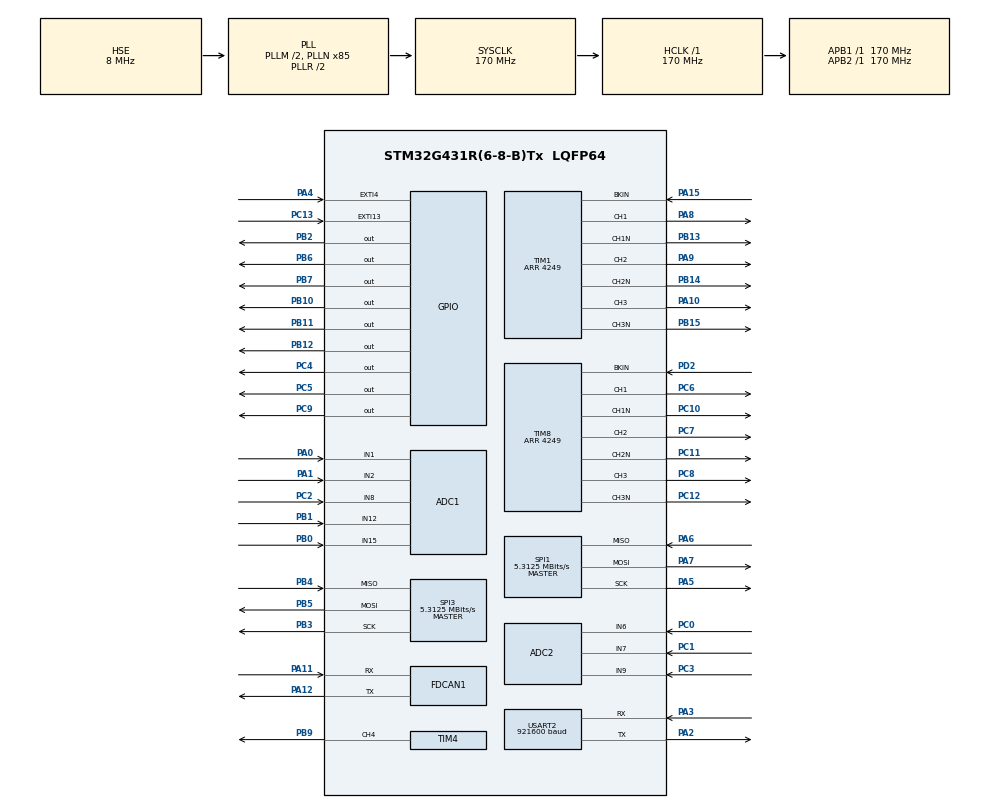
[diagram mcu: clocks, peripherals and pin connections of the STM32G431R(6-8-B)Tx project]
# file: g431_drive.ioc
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ADC1.Channel-0\#ChannelRegularConversion=ADC_CHANNEL_8
ADC1.Channel-4\#ChannelRegularConversion=ADC_CHANNEL_15
ADC1.Channel-5\#ChannelRegularConversion=ADC_CHANNEL_12
ADC1.Channel-6\#ChannelRegularConversion=ADC_CHANNEL_VREFINT
ADC1.EnableAnalogWatchDog3=false
ADC1.EnableInjectedConversion=ENABLE
ADC1.ExternalTrigConv=ADC_SOFTWARE_START
ADC1.ExternalTrigInjecConv=ADC_EXTERNALTRIGINJEC_T8_TRGO2
ADC1.InjNumberOfConversion=2
ADC1.InjectedChannel-2\#ChannelInjectedConversion=ADC_CHANNEL_1
ADC1.InjectedChannel-3\#ChannelInjectedConversion=ADC_CHANNEL_2
ADC1.InjectedOffsetNumber-2\#ChannelInjectedConversion=ADC_OFFSET_NONE
ADC1.InjectedOffsetNumber-3\#ChannelInjectedConversion=ADC_OFFSET_NONE
ADC1.InjectedRank-2\#ChannelInjectedConversion=1
ADC1.InjectedRank-3\#ChannelInjectedConversion=2
ADC1.InjectedSamplingTime-2\#ChannelInjectedConversion=ADC_SAMPLETIME_6CYCLES_5
ADC1.InjectedSamplingTime-3\#ChannelInjectedConversion=ADC_SAMPLETIME_6CYCLES_5
ADC1.NbrOfConversion=4
ADC1.NbrOfConversionFlag=1
ADC1.OffsetNumber-0\#ChannelRegularConversion=ADC_OFFSET_NONE
ADC1.OffsetNumber-4\#ChannelRegularConversion=ADC_OFFSET_NONE
ADC1.OffsetNumber-5\#ChannelRegularConversion=ADC_OFFSET_NONE
ADC1.OffsetNumber-6\#ChannelRegularConversion=ADC_OFFSET_NONE
ADC1.OversamplingMode=DISABLE
ADC1.Rank-0\#ChannelRegularConversion=1
ADC1.Rank-4\#ChannelRegularConversion=2
ADC1.Rank-5\#ChannelRegularConversion=3
ADC1.Rank-6\#ChannelRegularConversion=4
ADC1.SamplingTime-0\#ChannelRegularConversion=ADC_SAMPLETIME_92CYCLES_5
ADC1.SamplingTime-4\#ChannelRegularConversion=ADC_SAMPLETIME_92CYCLES_5
ADC1.SamplingTime-5\#ChannelRegularConversion=ADC_SAMPLETIME_92CYCLES_5
ADC1.SamplingTime-6\#ChannelRegularConversion=ADC_SAMPLETIME_247CYCLES_5
ADC1.master=1
ADC2.Channel-0\#ChannelRegularConversion=ADC_CHANNEL_9
ADC2.EnableInjectedConversion=ENABLE
ADC2.ExternalTrigConv=ADC_SOFTWARE_START
ADC2.ExternalTrigInjecConv=ADC_EXTERNALTRIGINJEC_T1_TRGO2
ADC2.InjNumberOfConversion=2
ADC2.InjectedChannel-1\#ChannelInjectedConversion=ADC_CHANNEL_6
ADC2.InjectedChannel-6\#ChannelInjectedConversion=ADC_CHANNEL_7
ADC2.InjectedOffsetNumber-1\#ChannelInjectedConversion=ADC_OFFSET_NONE
ADC2.InjectedOffsetNumber-6\#ChannelInjectedConversion=ADC_OFFSET_NONE
ADC2.InjectedRank-1\#ChannelInjectedConversion=1
ADC2.InjectedRank-6\#ChannelInjectedConversion=2
ADC2.InjectedSamplingTime-1\#ChannelInjectedConversion=ADC_SAMPLETIME_6CYCLES_5
ADC2.InjectedSamplingTime-6\#ChannelInjectedConversion=ADC_SAMPLETIME_6CYCLES_5
ADC2.NbrOfConversionFlag=1
ADC2.OffsetNumber-0\#ChannelRegularConversion=ADC_OFFSET_NONE
ADC2.Rank-0\#ChannelRegularConversion=1
ADC2.Rank1_Channel=ADC_CHANNEL_6
ADC2.Rank2_Channel=ADC_CHANNEL_7
ADC2.SamplingTime-0\#ChannelRegularConversion=ADC_SAMPLETIME_6CYCLES_5
Dma.Request0=USART2_TX
Dma.Request1=USART2_RX
Dma.USART2_RX.1.Direction=DMA_PERIPH_TO_MEMORY
Dma.USART2_RX.1.EventEnable=DISABLE
Dma.USART2_RX.1.Instance=DMA1_Channel2
Dma.USART2_RX.1.MemDataAlignment=DMA_MDATAALIGN_BYTE
Dma.USART2_RX.1.MemInc=DMA_MINC_ENABLE
Dma.USART2_RX.1.Mode=DMA_CIRCULAR
Dma.USART2_RX.1.PeriphDataAlignment=DMA_PDATAALIGN_BYTE
Dma.USART2_RX.1.PeriphInc=DMA_PINC_DISABLE
Dma.USART2_RX.1.Polarity=HAL_DMAMUX_REQ_GEN_RISING
Dma.USART2_RX.1.Priority=DMA_PRIORITY_LOW
Dma.USART2_RX.1.RequestNumber=1
Dma.USART2_RX.1.SignalID=NONE
Dma.USART2_RX.1.SyncEnable=DISABLE
Dma.USART2_RX.1.SyncPolarity=HAL_DMAMUX_SYNC_NO_EVENT
Dma.USART2_RX.1.SyncRequestNumber=1
Dma.USART2_RX.1.SyncSignalID=NONE
Dma.USART2_TX.0.Direction=DMA_MEMORY_TO_PERIPH
Dma.USART2_TX.0.EventEnable=DISABLE
Dma.USART2_TX.0.Instance=DMA1_Channel1
Dma.USART2_TX.0.MemDataAlignment=DMA_MDATAALIGN_BYTE
Dma.USART2_TX.0.MemInc=DMA_MINC_ENABLE
Dma.USART2_TX.0.Mode=DMA_NORMAL
Dma.USART2_TX.0.PeriphDataAlignment=DMA_PDATAALIGN_BYTE
Dma.USART2_TX.0.PeriphInc=DMA_PINC_DISABLE
Dma.USART2_TX.0.Polarity=HAL_DMAMUX_REQ_GEN_RISING
Dma.USART2_TX.0.Priority=DMA_PRIORITY_LOW
Dma.USART2_TX.0.RequestNumber=1
Dma.USART2_TX.0.SignalID=NONE
Dma.USART2_TX.0.SyncEnable=DISABLE
Dma.USART2_TX.0.SyncPolarity=HAL_DMAMUX_SYNC_NO_EVENT
Dma.USART2_TX.0.SyncRequestNumber=1
Dma.USART2_TX.0.SyncSignalID=NONE
FDCAN1.AutoRetransmission=ENABLE
FDCAN1.CalculateBaudRateNominal=500000
FDCAN1.CalculateTimeBitNominal=2000
FDCAN1.CalculateTimeQuantumNominal=125.0
FDCAN1.DataTimeSeg1=12
FDCAN1.DataTimeSeg2=3
FDCAN1.NominalPrescaler=1
FDCAN1.NominalTimeSeg1=12
FDCAN1.NominalTimeSeg2=3
FDCAN1.ProtocolException=DISABLE
FDCAN1.TransmitPause=DISABLE
IWDG.Prescaler=IWDG_PRESCALER_32
IWDG.Reload=40
IWDG.Window=20
Mcu.Family=STM32G4
Mcu.Name=STM32G431R(6-8-B)Tx
Mcu.Package=LQFP64
NVIC.ADC1_2_IRQn=true\:1\:0\:true\:false\:true\:true\:true\:true
NVIC.DMA1_Channel1_IRQn=true\:4\:0\:true\:false\:true\:false\:true\:true
NVIC.DMA1_Channel2_IRQn=true\:4\:0\:true\:false\:true\:false\:true\:true
NVIC.EXTI15_10_IRQn=true\:2\:0\:true\:false\:true\:true\:true\:true
NVIC.EXTI4_IRQn=true\:2\:0\:true\:false\:true\:true\:true\:true
NVIC.FDCAN1_IT0_IRQn=true\:3\:0\:true\:false\:true\:true\:true\:true
NVIC.PriorityGroup=NVIC_PRIORITYGROUP_4
NVIC.RCC_IRQn=true\:0\:0\:false\:false\:true\:true\:false\:true
NVIC.TIM1_BRK_TIM15_IRQn=true\:0\:0\:false\:false\:true\:true\:true\:true
NVIC.TIM8_BRK_IRQn=true\:0\:0\:false\:false\:true\:true\:true\:true
NVIC.USART2_IRQn=true\:4\:0\:true\:false\:true\:true\:true\:true
PA0.Mode=IN1-Single-Ended
PA0.Signal=ADC1_IN1
PA1.Mode=IN2-Single-Ended
PA1.Signal=ADC1_IN2
PA10.Signal=S_TIM1_CH3
PA11.Mode=FDCAN_Activate
PA11.Signal=FDCAN1_RX
PA12.Mode=FDCAN_Activate
PA12.Signal=FDCAN1_TX
PA13.Mode=Serial_Wire
PA13.Signal=SYS_JTMS-SWDIO
PA14.Mode=Serial_Wire
PA14.Signal=SYS_JTCK-SWCLK
PA15.Mode=Activate-Break-Input
PA15.Signal=TIM1_BKIN
PA2.Mode=Asynchronous
PA2.Signal=USART2_TX
PA3.Mode=Asynchronous
PA3.Signal=USART2_RX
PA4.GPIO_ModeDefaultEXTI=GPIO_MODE_IT_FALLING
PA4.GPIO_PuPd=GPIO_NOPULL
PA4.Signal=GPXTI4
PA5.GPIO_Speed=GPIO_SPEED_FREQ_MEDIUM
PA5.Mode=Full_Duplex_Master
PA5.Signal=SPI1_SCK
PA6.GPIO_Speed=GPIO_SPEED_FREQ_MEDIUM
PA6.Mode=Full_Duplex_Master
PA6.Signal=SPI1_MISO
PA7.GPIO_Speed=GPIO_SPEED_FREQ_MEDIUM
PA7.Mode=Full_Duplex_Master
PA7.Signal=SPI1_MOSI
PA8.Signal=S_TIM1_CH1
PA9.Signal=S_TIM1_CH2
PB0.Mode=IN15-Single-Ended
PB0.Signal=ADC1_IN15
PB1.Mode=IN12-Single-Ended
PB1.Signal=ADC1_IN12
PB10.GPIO_ModeDefaultOutputPP=GPIO_MODE_OUTPUT_PP
PB10.GPIO_Speed=GPIO_SPEED_FREQ_LOW
PB10.PinState=GPIO_PIN_RESET
PB10.Signal=GPIO_Output
PB11.GPIO_ModeDefaultOutputPP=GPIO_MODE_OUTPUT_PP
PB11.GPIO_Speed=GPIO_SPEED_FREQ_LOW
PB11.PinState=GPIO_PIN_SET
PB11.Signal=GPIO_Output
PB12.GPIO_ModeDefaultOutputPP=GPIO_MODE_OUTPUT_PP
PB12.GPIO_Speed=GPIO_SPEED_FREQ_LOW
PB12.PinState=GPIO_PIN_SET
PB12.Signal=GPIO_Output
PB13.Mode=PWM Generation1 CH1 CH1N
PB13.Signal=TIM1_CH1N
PB14.Mode=PWM Generation2 CH2 CH2N
PB14.Signal=TIM1_CH2N
PB15.Mode=PWM Generation3 CH3 CH3N
PB15.Signal=TIM1_CH3N
PB2.GPIO_ModeDefaultOutputPP=GPIO_MODE_OUTPUT_PP
PB2.GPIO_Speed=GPIO_SPEED_FREQ_LOW
PB2.PinState=GPIO_PIN_RESET
PB2.Signal=GPIO_Output
PB3.GPIO_Speed=GPIO_SPEED_FREQ_MEDIUM
PB3.Mode=Full_Duplex_Master
PB3.Signal=SPI3_SCK
PB4.GPIO_Speed=GPIO_SPEED_FREQ_MEDIUM
PB4.Mode=Full_Duplex_Master
PB4.Signal=SPI3_MISO
PB5.GPIO_Speed=GPIO_SPEED_FREQ_MEDIUM
PB5.Mode=Full_Duplex_Master
PB5.Signal=SPI3_MOSI
PB6.GPIO_ModeDefaultOutputPP=GPIO_MODE_OUTPUT_PP
PB6.GPIO_Speed=GPIO_SPEED_FREQ_LOW
PB6.PinState=GPIO_PIN_SET
PB6.Signal=GPIO_Output
PB7.GPIO_ModeDefaultOutputPP=GPIO_MODE_OUTPUT_PP
PB7.GPIO_Speed=GPIO_SPEED_FREQ_LOW
PB7.PinState=GPIO_PIN_SET
PB7.Signal=GPIO_Output
PB9.Signal=S_TIM4_CH4
PC0.Mode=IN6-Single-Ended
PC0.Signal=ADC2_IN6
PC1.Mode=IN7-Single-Ended
PC1.Signal=ADC2_IN7
PC10.Mode=PWM Generation1 CH1 CH1N
PC10.Signal=TIM8_CH1N
PC11.Mode=PWM Generation2 CH2 CH2N
PC11.Signal=TIM8_CH2N
PC12.Mode=PWM Generation3 CH3 CH3N
PC12.Signal=TIM8_CH3N
PC13.GPIO_ModeDefaultEXTI=GPIO_MODE_IT_FALLING
PC13.Signal=GPXTI13
PC2.Mode=IN8-Single-Ended
PC2.Signal=ADC1_IN8
PC3.Mode=IN9-Single-Ended
PC3.Signal=ADC2_IN9
PC4.GPIO_ModeDefaultOutputPP=GPIO_MODE_OUTPUT_PP
PC4.GPIO_Speed=GPIO_SPEED_FREQ_LOW
PC4.PinState=GPIO_PIN_SET
PC4.Signal=GPIO_Output
PC5.GPIO_ModeDefaultOutputPP=GPIO_MODE_OUTPUT_PP
PC5.GPIO_Speed=GPIO_SPEED_FREQ_LOW
PC5.PinState=GPIO_PIN_SET
PC5.Signal=GPIO_Output
PC6.Signal=S_TIM8_CH1
PC7.Signal=S_TIM8_CH2
PC8.Signal=S_TIM8_CH3
PC9.GPIO_ModeDefaultOutputPP=GPIO_MODE_OUTPUT_PP
PC9.GPIO_Speed=GPIO_SPEED_FREQ_LOW
PC9.PinState=GPIO_PIN_SET
PC9.Signal=GPIO_Output
PD2.Mode=Activate-Break-Input
PD2.Signal=TIM8_BKIN
PF0-OSC_IN.Mode=HSE-External-Oscillator
PF0-OSC_IN.Signal=RCC_OSC_IN
PF1-OSC_OUT.Mode=HSE-External-Oscillator
PF1-OSC_OUT.Signal=RCC_OSC_OUT
ProjectManager.HeapSize=0x200
ProjectManager.StackSize=0x400
ProjectManager.TargetToolchain=MDK-ARM V5.32
RCC.ADC12Freq_Value=170000000
RCC.AHBFreq_Value=170000000
RCC.APB1Freq_Value=170000000
RCC.APB1TimFreq_Value=170000000
RCC.APB2Freq_Value=170000000
RCC.APB2TimFreq_Value=170000000
RCC.CortexFreq_Value=170000000
RCC.EXTERNAL_CLOCK_VALUE=12288000
RCC.EnbaleCSS=true
RCC.FDCANCLockSelection=RCC_FDCANCLKSOURCE_HSE
RCC.HCLKFreq_Value=170000000
RCC.HSE_VALUE=8000000
RCC.HSI48_VALUE=48000000
RCC.HSI_VALUE=16000000
RCC.LSE_VALUE=32768
RCC.PLLM=RCC_PLLM_DIV2
RCC.PLLN=85
RCC.PLLSourceVirtual=RCC_PLLSOURCE_HSE
RCC.SYSCLKFreq_VALUE=170000000
RCC.SYSCLKSource=RCC_SYSCLKSOURCE_PLLCLK
RCC.USBFreq_Value=170000000
RCC.VCOOutputFreq_Value=340000000
SH.S_TIM1_CH1.0=TIM1_CH1,PWM Generation1 CH1 CH1N
SH.S_TIM1_CH2.0=TIM1_CH2,PWM Generation2 CH2 CH2N
SH.S_TIM1_CH3.0=TIM1_CH3,PWM Generation3 CH3 CH3N
SH.S_TIM4_CH4.0=TIM4_CH4,PWM Generation4 CH4
SH.S_TIM8_CH1.0=TIM8_CH1,PWM Generation1 CH1 CH1N
SH.S_TIM8_CH2.0=TIM8_CH2,PWM Generation2 CH2 CH2N
SH.S_TIM8_CH3.0=TIM8_CH3,PWM Generation3 CH3 CH3N
SPI1.BaudRatePrescaler=SPI_BAUDRATEPRESCALER_32
SPI1.CLKPhase=SPI_PHASE_2EDGE
SPI1.CLKPolarity=SPI_POLARITY_HIGH
SPI1.CalculateBaudRate=5.3125 MBits/s
SPI1.DataSize=SPI_DATASIZE_8BIT
SPI1.Direction=SPI_DIRECTION_2LINES
SPI1.Mode=SPI_MODE_MASTER
SPI1.VirtualType=VM_MASTER
SPI3.BaudRatePrescaler=SPI_BAUDRATEPRESCALER_32
SPI3.CLKPhase=SPI_PHASE_2EDGE
SPI3.CLKPolarity=SPI_POLARITY_HIGH
SPI3.CalculateBaudRate=5.3125 MBits/s
SPI3.DataSize=SPI_DATASIZE_8BIT
SPI3.Direction=SPI_DIRECTION_2LINES
SPI3.Mode=SPI_MODE_MASTER
SPI3.VirtualType=VM_MASTER
TIM1.Break2Polarity=TIM_BREAK2POLARITY_LOW
TIM1.BreakFilter=3
TIM1.BreakPolarity=TIM_BREAKPOLARITY_LOW
TIM1.Channel-PWM\ Generation1\ CH1\ CH1N=TIM_CHANNEL_1
TIM1.Channel-PWM\ Generation2\ CH2\ CH2N=TIM_CHANNEL_2
TIM1.Channel-PWM\ Generation3\ CH3\ CH3N=TIM_CHANNEL_3
TIM1.Channel-PWM\ Generation5\ No\ Output=TIM_CHANNEL_5
TIM1.CounterMode=TIM_COUNTERMODE_CENTERALIGNED1
TIM1.LockLevel=TIM_LOCKLEVEL_3
TIM1.PeriodNoDither=4249
TIM1.PulseNoDither_5=4200
TIM1.TIM_MasterOutputTrigger2=TIM_TRGO2_OC5REF
TIM4.Channel-PWM\ Generation4\ CH4=TIM_CHANNEL_4
TIM4.PeriodNoDither=99
TIM4.Prescaler=169
TIM8.Break2Polarity=TIM_BREAK2POLARITY_LOW
TIM8.BreakFilter=3
TIM8.BreakPolarity=TIM_BREAKPOLARITY_LOW
TIM8.Channel-PWM\ Generation1\ CH1\ CH1N=TIM_CHANNEL_1
TIM8.Channel-PWM\ Generation2\ CH2\ CH2N=TIM_CHANNEL_2
TIM8.Channel-PWM\ Generation3\ CH3\ CH3N=TIM_CHANNEL_3
TIM8.Channel-PWM\ Generation5\ No\ Output=TIM_CHANNEL_5
TIM8.CounterMode=TIM_COUNTERMODE_CENTERALIGNED1
TIM8.LockLevel=TIM_LOCKLEVEL_3
TIM8.PeriodNoDither=4249
TIM8.PulseNoDither_5=4200
TIM8.TIM_MasterOutputTrigger2=TIM_TRGO2_OC5REF
USART2.BaudRate=921600
USART2.VirtualMode-Asynchronous=VM_ASYNC
VP_ADC1_Vref_Input.Mode=IN-Vrefint
VP_IWDG_VS_IWDG.Mode=IWDG_Activate
VP_SYS_VS_DBSignals.Mode=DisableDeadBatterySignals
VP_TIM1_VS_ClockSourceINT.Mode=Internal
VP_TIM1_VS_no_output5.Mode=PWM Generation5 No Output
VP_TIM4_VS_ClockSourceINT.Mode=Internal
VP_TIM8_VS_ClockSourceINT.Mode=Internal
VP_TIM8_VS_no_output5.Mode=PWM Generation5 No Output
board=custom

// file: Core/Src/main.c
/* USER CODE BEGIN Header */
/**
  ******************************************************************************
  * @file           : main.c
  * @brief          : Main program body
  ******************************************************************************
  * @attention
  *
  * Copyright (c) 2026 STMicroelectronics.
  * All rights reserved.
  *
  * This software is licensed under terms that can be found in the LICENSE file
  * in the root directory of this software component.
  * If no LICENSE file comes with this software, it is provided AS-IS.
  *
  ******************************************************************************
  */
/* USER CODE END Header */
#include "main.h"
#include "adc.h"
#include "dma.h"
#include "fdcan.h"
#include "spi.h"
#include "tim.h"
#include "usart.h"
#include "gpio.h"

/* USER CODE BEGIN Includes */

#include "headline.h" /* 统一 include 入口：HAL、标准库与全部模块头在此聚合，各 .c 只 include 本头文件（约定见端级 CLAUDE.md） */

/* USER CODE END Includes */

void SystemClock_Config(void);

int main(void)
{

  /* MCU Configuration--------------------------------------------------------*/

  /* Reset of all peripherals, Initializes the Flash interface and the Systick. */
  HAL_Init();

  /* Configure the system clock */
  SystemClock_Config();

  /* Initialize all configured peripherals */
  MX_GPIO_Init();
  MX_DMA_Init();
  MX_TIM1_Init();
  MX_ADC1_Init();
  MX_ADC2_Init();
  MX_TIM4_Init();
  MX_TIM8_Init();
  MX_USART2_UART_Init();
  MX_FDCAN1_Init();
  MX_SPI1_Init();
  MX_SPI3_Init();
  /* USER CODE BEGIN 2 */

  app_init(); /* 统一初始化入口：各模块初始化在此聚合，各 .c 只调用本函数（约定见端级 CLAUDE.md） */

  /* USER CODE END 2 */

  /* Infinite loop */
  /* USER CODE BEGIN WHILE */
  while (1)
  {

    app_main(); /* 统一主循环入口：各模块主循环在此聚合，各 .c 只调用本函数（约定见端级 CLAUDE.md） */

    /* USER CODE END WHILE */

  }
}

void SystemClock_Config(void)
{
  RCC_OscInitTypeDef RCC_OscInitStruct = {0};
  RCC_ClkInitTypeDef RCC_ClkInitStruct = {0};

  /** Configure the main internal regulator output voltage
  */
  HAL_PWREx_ControlVoltageScaling(PWR_REGULATOR_VOLTAGE_SCALE1_BOOST);

  /** Initializes the RCC Oscillators according to the specified parameters
  * in the RCC_OscInitTypeDef structure.
  */
  RCC_OscInitStruct.OscillatorType = RCC_OSCILLATORTYPE_LSI|RCC_OSCILLATORTYPE_HSE;
  RCC_OscInitStruct.HSEState = RCC_HSE_ON;
  RCC_OscInitStruct.LSIState = RCC_LSI_ON;
  RCC_OscInitStruct.PLL.PLLState = RCC_PLL_ON;
  RCC_OscInitStruct.PLL.PLLSource = RCC_PLLSOURCE_HSE;
  RCC_OscInitStruct.PLL.PLLM = RCC_PLLM_DIV2;
  RCC_OscInitStruct.PLL.PLLN = 85;
  RCC_OscInitStruct.PLL.PLLP = RCC_PLLP_DIV2;
  RCC_OscInitStruct.PLL.PLLQ = RCC_PLLQ_DIV2;
  RCC_OscInitStruct.PLL.PLLR = RCC_PLLR_DIV2;
  if (HAL_RCC_OscConfig(&RCC_OscInitStruct) != HAL_OK)
  {
    Error_Handler();
  }

  /** Initializes the CPU, AHB and APB buses clocks
  */
  RCC_ClkInitStruct.ClockType = RCC_CLOCKTYPE_HCLK|RCC_CLOCKTYPE_SYSCLK
                              |RCC_CLOCKTYPE_PCLK1|RCC_CLOCKTYPE_PCLK2;
  RCC_ClkInitStruct.SYSCLKSource = RCC_SYSCLKSOURCE_PLLCLK;
  RCC_ClkInitStruct.AHBCLKDivider = RCC_SYSCLK_DIV1;
  RCC_ClkInitStruct.APB1CLKDivider = RCC_HCLK_DIV1;
  RCC_ClkInitStruct.APB2CLKDivider = RCC_HCLK_DIV1;

  if (HAL_RCC_ClockConfig(&RCC_ClkInitStruct, FLASH_LATENCY_4) != HAL_OK)
  {
    Error_Handler();
  }

  /** Enables the Clock Security System
  */
  HAL_RCC_EnableCSS();
}

void Error_Handler(void)
{
  __disable_irq();
  while (1)
  {
  }
}
